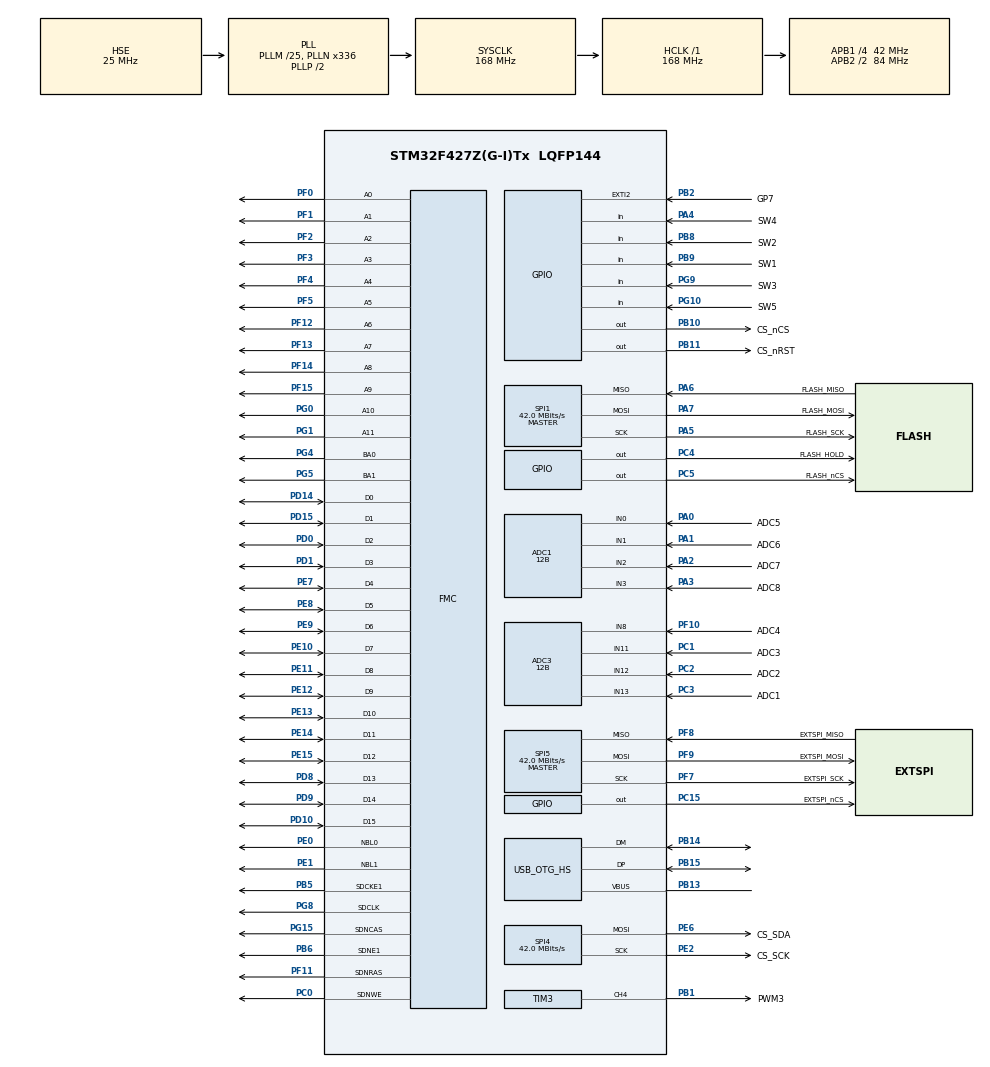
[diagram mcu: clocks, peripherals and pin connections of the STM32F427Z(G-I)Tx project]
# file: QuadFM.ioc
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ADC1.Channel-0\#ChannelRegularConversion=ADC_CHANNEL_0
ADC1.ClockPrescaler=ADC_CLOCK_SYNC_PCLK_DIV8
ADC1.ContinuousConvMode=DISABLE
ADC1.DMAContinuousRequests=DISABLE
ADC1.DataAlign=ADC_DATAALIGN_RIGHT
ADC1.DiscontinuousConvMode=DISABLE
ADC1.EOCSelection=ADC_EOC_SINGLE_CONV
ADC1.EnableAnalogWatchDog=false
ADC1.ExternalTrigConv=ADC_SOFTWARE_START
ADC1.ExternalTrigConvEdge=ADC_EXTERNALTRIGCONVEDGE_NONE
ADC1.InjNumberOfConversion=0
ADC1.NbrOfConversion=1
ADC1.NbrOfConversionFlag=1
ADC1.Rank-0\#ChannelRegularConversion=1
ADC1.Resolution=ADC_RESOLUTION_12B
ADC1.SamplingTime-0\#ChannelRegularConversion=ADC_SAMPLETIME_3CYCLES
ADC1.ScanConvMode=DISABLE
ADC1.master=1
ADC3.Channel-31\#ChannelRegularConversion=ADC_CHANNEL_12
ADC3.Channel-32\#ChannelRegularConversion=ADC_CHANNEL_8
ADC3.Channel-33\#ChannelRegularConversion=ADC_CHANNEL_11
ADC3.Channel-34\#ChannelRegularConversion=ADC_CHANNEL_13
ADC3.ClockPrescaler=ADC_CLOCK_SYNC_PCLK_DIV8
ADC3.ContinuousConvMode=ENABLE
ADC3.DMAContinuousRequests=ENABLE
ADC3.DataAlign=ADC_DATAALIGN_RIGHT
ADC3.DiscontinuousConvMode=DISABLE
ADC3.EOCSelection=ADC_EOC_SEQ_CONV
ADC3.EnableAnalogWatchDog=false
ADC3.ExternalTrigConv=ADC_SOFTWARE_START
ADC3.ExternalTrigConvEdge=ADC_EXTERNALTRIGCONVEDGE_NONE
ADC3.InjNumberOfConversion=0
ADC3.NbrOfConversion=4
ADC3.NbrOfConversionFlag=1
ADC3.Rank-31\#ChannelRegularConversion=1
ADC3.Rank-32\#ChannelRegularConversion=2
ADC3.Rank-33\#ChannelRegularConversion=3
ADC3.Rank-34\#ChannelRegularConversion=4
ADC3.Resolution=ADC_RESOLUTION_12B
ADC3.SamplingTime-31\#ChannelRegularConversion=ADC_SAMPLETIME_144CYCLES
ADC3.SamplingTime-32\#ChannelRegularConversion=ADC_SAMPLETIME_144CYCLES
ADC3.SamplingTime-33\#ChannelRegularConversion=ADC_SAMPLETIME_144CYCLES
ADC3.SamplingTime-34\#ChannelRegularConversion=ADC_SAMPLETIME_144CYCLES
ADC3.ScanConvMode=ENABLE
Dma.ADC1.1.Direction=DMA_PERIPH_TO_MEMORY
Dma.ADC1.1.FIFOMode=DMA_FIFOMODE_DISABLE
Dma.ADC1.1.Instance=DMA2_Stream4
Dma.ADC1.1.MemDataAlignment=DMA_MDATAALIGN_HALFWORD
Dma.ADC1.1.MemInc=DMA_MINC_ENABLE
Dma.ADC1.1.Mode=DMA_NORMAL
Dma.ADC1.1.PeriphDataAlignment=DMA_PDATAALIGN_HALFWORD
Dma.ADC1.1.PeriphInc=DMA_PINC_DISABLE
Dma.ADC1.1.Priority=DMA_PRIORITY_LOW
Dma.ADC3.0.Direction=DMA_PERIPH_TO_MEMORY
Dma.ADC3.0.FIFOMode=DMA_FIFOMODE_DISABLE
Dma.ADC3.0.Instance=DMA2_Stream0
Dma.ADC3.0.MemDataAlignment=DMA_MDATAALIGN_HALFWORD
Dma.ADC3.0.MemInc=DMA_MINC_ENABLE
Dma.ADC3.0.Mode=DMA_CIRCULAR
Dma.ADC3.0.PeriphDataAlignment=DMA_PDATAALIGN_HALFWORD
Dma.ADC3.0.PeriphInc=DMA_PINC_DISABLE
Dma.ADC3.0.Priority=DMA_PRIORITY_LOW
Dma.Request0=ADC3
Dma.Request1=ADC1
FMC.CASLatency1=FMC_SDRAM_CAS_LATENCY_3
FMC.ExitSelfRefreshDelay1=6
FMC.LoadToActiveDelay1=2
FMC.RCDDelay1=2
FMC.RPDelay1=2
FMC.RPDelay2=2
FMC.ReadBurst1=FMC_SDRAM_RBURST_ENABLE
FMC.ReadBurst2=FMC_SDRAM_RBURST_ENABLE
FMC.ReadPipeDelay1=FMC_SDRAM_RPIPE_DELAY_0
FMC.RowCycleDelay1=6
FMC.RowCycleDelay2=6
FMC.SDClockPeriod1=FMC_SDRAM_CLOCK_PERIOD_2
FMC.SDClockPeriod2=FMC_SDRAM_CLOCK_PERIOD_2
FMC.SelfRefreshTime1=4
FMC.WriteRecoveryTime1=2
Mcu.Family=STM32F4
Mcu.Name=STM32F427Z(G-I)Tx
Mcu.Package=LQFP144
NVIC.DMA2_Stream0_IRQn=true\:0\:0\:true\:false\:true
NVIC.DMA2_Stream4_IRQn=true\:5\:0\:true\:false\:true
NVIC.EXTI2_IRQn=true\:10\:0\:true\:false\:true
NVIC.OTG_HS_IRQn=true\:8\:0\:true\:false\:true
NVIC.PriorityGroup=NVIC_PRIORITYGROUP_4
PA0/WKUP.GPIO_Label=ADC5
PA0/WKUP.Signal=ADCx_IN0
PA1.GPIO_Label=ADC6
PA1.Signal=SharedAnalog_PA1
PA13.Mode=Trace_Asynchronous_SW
PA13.Signal=SYS_JTMS-SWDIO
PA14.Mode=Trace_Asynchronous_SW
PA14.Signal=SYS_JTCK-SWCLK
PA2.GPIO_Label=ADC7
PA2.Signal=ADCx_IN2
PA3.GPIO_Label=ADC8
PA3.Signal=ADCx_IN3
PA4.GPIO_Label=SW4
PA4.Signal=GPIO_Input
PA5.GPIO_Label=FLASH_SCK
PA5.Mode=Full_Duplex_Master
PA5.Signal=SPI1_SCK
PA6.GPIO_Label=FLASH_MISO
PA6.Mode=Full_Duplex_Master
PA6.Signal=SPI1_MISO
PA7.GPIO_Label=FLASH_MOSI
PA7.Mode=Full_Duplex_Master
PA7.Signal=SPI1_MOSI
PB1.GPIO_Label=PWM3
PB1.Signal=S_TIM3_CH4
PB10.GPIO_Label=CS_nCS
PB10.Signal=GPIO_Output
PB11.GPIO_Label=CS_nRST
PB11.Signal=GPIO_Output
PB13.Mode=Activate_VBUS_FS
PB13.Signal=USB_OTG_HS_VBUS
PB14.Mode=Device_Only_FS
PB14.Signal=USB_OTG_HS_DM
PB15.Mode=Device_Only_FS
PB15.Signal=USB_OTG_HS_DP
PB2/BOOT1.GPIO_Label=GP7
PB2/BOOT1.GPIO_ModeDefaultEXTI=GPIO_MODE_IT_RISING_FALLING
PB2/BOOT1.Signal=GPXTI2
PB3.Mode=Trace_Asynchronous_SW
PB3.Signal=SYS_JTDO-SWO
PB5.Mode=SdramChipSelect2_1
PB5.Signal=FMC_SDCKE1
PB6.Mode=SdramChipSelect2_1
PB6.Signal=FMC_SDNE1
PB8.GPIO_Label=SW2
PB8.Signal=GPIO_Input
PB9.GPIO_Label=SW1
PB9.Signal=GPIO_Input
PC0.Signal=FMC_SDNWE
PC1.GPIO_Label=ADC3
PC1.Signal=ADCx_IN11
PC15/OSC32_OUT.GPIO_Label=EXTSPI_nCS
PC15/OSC32_OUT.Signal=GPIO_Output
PC2.GPIO_Label=ADC2
PC2.Signal=ADCx_IN12
PC3.GPIO_Label=ADC1
PC3.Signal=ADCx_IN13
PC4.GPIO_Label=FLASH_HOLD
PC4.Signal=GPIO_Output
PC5.GPIO_Label=FLASH_nCS
PC5.Signal=GPIO_Output
PD0.Signal=FMC_D2_DA2
PD1.Signal=FMC_D3_DA3
PD10.Signal=FMC_D15_DA15
PD14.Signal=FMC_D0_DA0
PD15.Signal=FMC_D1_DA1
PD8.Signal=FMC_D13_DA13
PD9.Signal=FMC_D14_DA14
PE0.Signal=FMC_NBL0
PE1.Signal=FMC_NBL1
PE10.Signal=FMC_D7_DA7
PE11.Signal=FMC_D8_DA8
PE12.Signal=FMC_D9_DA9
PE13.Signal=FMC_D10_DA10
PE14.Signal=FMC_D11_DA11
PE15.Signal=FMC_D12_DA12
PE2.GPIO_Label=CS_SCK
PE2.Mode=TX_Only_Simplex_Unidirect_Master
PE2.Signal=SPI4_SCK
PE6.GPIO_Label=CS_SDA
PE6.Mode=TX_Only_Simplex_Unidirect_Master
PE6.Signal=SPI4_MOSI
PE7.Signal=FMC_D4_DA4
PE8.Signal=FMC_D5_DA5
PE9.Signal=FMC_D6_DA6
PF0.Signal=FMC_A0
PF1.Signal=FMC_A1
PF10.GPIO_Label=ADC4
PF10.Mode=IN8
PF10.Signal=ADC3_IN8
PF11.Signal=FMC_SDNRAS
PF12.Signal=FMC_A6
PF13.Signal=FMC_A7
PF14.Signal=FMC_A8
PF15.Signal=FMC_A9
PF2.Signal=FMC_A2
PF3.Signal=FMC_A3
PF4.Signal=FMC_A4
PF5.Signal=FMC_A5
PF7.GPIO_Label=EXTSPI_SCK
PF7.Mode=Full_Duplex_Master
PF7.Signal=SPI5_SCK
PF8.GPIO_Label=EXTSPI_MISO
PF8.Mode=Full_Duplex_Master
PF8.Signal=SPI5_MISO
PF9.GPIO_Label=EXTSPI_MOSI
PF9.Mode=Full_Duplex_Master
PF9.Signal=SPI5_MOSI
PG0.Signal=FMC_A10
PG1.Signal=FMC_A11
PG10.GPIO_Label=SW5
PG10.Signal=GPIO_Input
PG15.Signal=FMC_SDNCAS
PG4.Signal=FMC_A14_BA0
PG5.Signal=FMC_A15_BA1
PG8.Signal=FMC_SDCLK
PG9.GPIO_Label=SW3
PG9.Signal=GPIO_Input
PH0/OSC_IN.Mode=HSE-External-Oscillator
PH0/OSC_IN.Signal=RCC_OSC_IN
PH1/OSC_OUT.Mode=HSE-External-Oscillator
PH1/OSC_OUT.Signal=RCC_OSC_OUT
ProjectManager.HeapSize=0x200
ProjectManager.StackSize=0x400
ProjectManager.TargetToolchain=MDK-ARM V5
RCC.48MHZClocksFreq_Value=48000000
RCC.AHBFreq_Value=168000000
RCC.APB1CLKDivider=RCC_HCLK_DIV4
RCC.APB1Freq_Value=42000000
RCC.APB1TimFreq_Value=84000000
RCC.APB2CLKDivider=RCC_HCLK_DIV2
RCC.APB2Freq_Value=84000000
RCC.APB2TimFreq_Value=168000000
RCC.CortexFreq_Value=168000000
RCC.HCLKFreq_Value=168000000
RCC.HSE_VALUE=25000000
RCC.HSI_VALUE=16000000
RCC.LSE_VALUE=32768
RCC.PLLM=25
RCC.PLLN=336
RCC.PLLQ=7
RCC.PLLSAIN=100
RCC.SYSCLKFreq_VALUE=168000000
RCC.SYSCLKSource=RCC_SYSCLKSOURCE_PLLCLK
RCC.USBFreq_Value=48000000
RCC.VCOOutputFreq_Value=336000000
SH.ADCx_IN0.0=ADC1_IN0,IN0
SH.ADCx_IN11.0=ADC3_IN11,IN11
SH.ADCx_IN12.0=ADC3_IN12,IN12
SH.ADCx_IN13.0=ADC3_IN13,IN13
SH.ADCx_IN2.0=ADC1_IN2,IN2
SH.ADCx_IN3.0=ADC1_IN3,IN3
SH.FMC_A0.0=FMC_A0,12b-sda1
SH.FMC_A1.0=FMC_A1,12b-sda1
SH.FMC_A10.0=FMC_A10,12b-sda1
SH.FMC_A11.0=FMC_A11,12b-sda1
SH.FMC_A14_BA0.0=FMC_BA0,FourSdramBanks1
SH.FMC_A15_BA1.0=FMC_BA1,FourSdramBanks1
SH.FMC_A2.0=FMC_A2,12b-sda1
SH.FMC_A3.0=FMC_A3,12b-sda1
SH.FMC_A4.0=FMC_A4,12b-sda1
SH.FMC_A5.0=FMC_A5,12b-sda1
SH.FMC_A6.0=FMC_A6,12b-sda1
SH.FMC_A7.0=FMC_A7,12b-sda1
SH.FMC_A8.0=FMC_A8,12b-sda1
SH.FMC_A9.0=FMC_A9,12b-sda1
SH.FMC_D0_DA0.0=FMC_D0,sd-16b-d1
SH.FMC_D10_DA10.0=FMC_D10,sd-16b-d1
SH.FMC_D11_DA11.0=FMC_D11,sd-16b-d1
SH.FMC_D12_DA12.0=FMC_D12,sd-16b-d1
SH.FMC_D13_DA13.0=FMC_D13,sd-16b-d1
SH.FMC_D14_DA14.0=FMC_D14,sd-16b-d1
SH.FMC_D15_DA15.0=FMC_D15,sd-16b-d1
SH.FMC_D1_DA1.0=FMC_D1,sd-16b-d1
SH.FMC_D2_DA2.0=FMC_D2,sd-16b-d1
SH.FMC_D3_DA3.0=FMC_D3,sd-16b-d1
SH.FMC_D4_DA4.0=FMC_D4,sd-16b-d1
SH.FMC_D5_DA5.0=FMC_D5,sd-16b-d1
SH.FMC_D6_DA6.0=FMC_D6,sd-16b-d1
SH.FMC_D7_DA7.0=FMC_D7,sd-16b-d1
SH.FMC_D8_DA8.0=FMC_D8,sd-16b-d1
SH.FMC_D9_DA9.0=FMC_D9,sd-16b-d1
SH.FMC_NBL0.0=FMC_NBL0,Sd2ByteEnable1
SH.FMC_NBL1.0=FMC_NBL1,Sd2ByteEnable1
SH.FMC_SDCLK.0=FMC_SDCLK,12b-sda1
SH.FMC_SDNCAS.0=FMC_SDNCAS,12b-sda1
SH.FMC_SDNRAS.0=FMC_SDNRAS,12b-sda1
SH.FMC_SDNWE.0=FMC_SDNWE,12b-sda1
SH.S_TIM3_CH4.0=TIM3_CH4,PWM Generation4 CH4
SH.SharedAnalog_PA1.0=GPIO_Analog
SH.SharedAnalog_PA1.1=ADC1_IN1,IN1
SPI1.CalculateBaudRate=42.0 MBits/s
SPI1.Direction=SPI_DIRECTION_2LINES
SPI1.Mode=SPI_MODE_MASTER
SPI1.VirtualType=VM_MASTER
SPI4.CalculateBaudRate=42.0 MBits/s
SPI4.Direction=SPI_DIRECTION_2LINES
SPI4.Mode=SPI_MODE_MASTER
SPI4.VirtualType=VM_MASTER
SPI5.CalculateBaudRate=42.0 MBits/s
SPI5.Direction=SPI_DIRECTION_2LINES
SPI5.Mode=SPI_MODE_MASTER
SPI5.VirtualType=VM_MASTER
TIM3.Channel-PWM\ Generation4\ CH4=TIM_CHANNEL_4
TIM3.Period=1000
TIM3.Prescaler=100
TIM3.Pulse-PWM\ Generation4\ CH4=1000
USB_OTG_HS.VirtualMode-Device_Only_FS=Device_Only_FS
board=QuadFM

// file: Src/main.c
/**
  ******************************************************************************
  * File Name          : main.c
  * Description        : Main program body
  ******************************************************************************
  ** This notice applies to any and all portions of this file
  * that are not between comment pairs USER CODE BEGIN and
  * USER CODE END. Other portions of this file, whether
  * inserted by the user or by software development tools
  * are owned by their respective copyright owners.
  *
  * COPYRIGHT(c) 2017 STMicroelectronics
  *
  * Redistribution and use in source and binary forms, with or without modification,
  * are permitted provided that the following conditions are met:
  *   1. Redistributions of source code must retain the above copyright notice,
  *      this list of conditions and the following disclaimer.
  *   2. Redistributions in binary form must reproduce the above copyright notice,
  *      this list of conditions and the following disclaimer in the documentation
  *      and/or other materials provided with the distribution.
  *   3. Neither the name of STMicroelectronics nor the names of its contributors
  *      may be used to endorse or promote products derived from this software
  *      without specific prior written permission.
  *
  * THIS SOFTWARE IS PROVIDED BY THE COPYRIGHT HOLDERS AND CONTRIBUTORS "AS IS"
  * AND ANY EXPRESS OR IMPLIED WARRANTIES, INCLUDING, BUT NOT LIMITED TO, THE
  * IMPLIED WARRANTIES OF MERCHANTABILITY AND FITNESS FOR A PARTICULAR PURPOSE ARE
  * DISCLAIMED. IN NO EVENT SHALL THE COPYRIGHT HOLDER OR CONTRIBUTORS BE LIABLE
  * FOR ANY DIRECT, INDIRECT, INCIDENTAL, SPECIAL, EXEMPLARY, OR CONSEQUENTIAL
  * DAMAGES (INCLUDING, BUT NOT LIMITED TO, PROCUREMENT OF SUBSTITUTE GOODS OR
  * SERVICES; LOSS OF USE, DATA, OR PROFITS; OR BUSINESS INTERRUPTION) HOWEVER
  * CAUSED AND ON ANY THEORY OF LIABILITY, WHETHER IN CONTRACT, STRICT LIABILITY,
  * OR TORT (INCLUDING NEGLIGENCE OR OTHERWISE) ARISING IN ANY WAY OUT OF THE USE
  * OF THIS SOFTWARE, EVEN IF ADVISED OF THE POSSIBILITY OF SUCH DAMAGE.
  *
  ******************************************************************************
  */
#include "main.h"
#include "stm32f4xx_hal.h"

/* USER CODE BEGIN Includes */

#include "HAL_ToggleSwitches.h"
#include "TLC5971.h"
#include "Flash_S25FL.h"

/* USER CODE END Includes */

ADC_HandleTypeDef hadc1;
ADC_HandleTypeDef hadc3;
DMA_HandleTypeDef hdma_adc1;
DMA_HandleTypeDef hdma_adc3;

SPI_HandleTypeDef hspi1;
SPI_HandleTypeDef hspi4;
SPI_HandleTypeDef hspi5;

TIM_HandleTypeDef htim3;

PCD_HandleTypeDef hpcd_USB_OTG_HS;

SDRAM_HandleTypeDef hsdram1;

/* USER CODE BEGIN PV */
/* Private variables ---------------------------------------------------------*/

/* USER CODE END PV */

void SystemClock_Config(void);
static void MX_GPIO_Init(void);
static void MX_DMA_Init(void);
static void MX_ADC3_Init(void);
static void MX_FMC_Init(void);
static void MX_SPI5_Init(void);
static void MX_TIM3_Init(void);
static void MX_ADC1_Init(void);
static void MX_SPI1_Init(void);
static void MX_SPI4_Init(void);
static void MX_USB_OTG_HS_PCD_Init(void);

void HAL_TIM_MspPostInit(TIM_HandleTypeDef *htim);

/* USER CODE BEGIN PFP */
/* Private function prototypes -----------------------------------------------*/

/* USER CODE END PFP */

int main(void)
{

  /* MCU Configuration----------------------------------------------------------*/

  /* Reset of all peripherals, Initializes the Flash interface and the Systick. */
  HAL_Init();

  /* Configure the system clock */
  SystemClock_Config();

  /* Initialize all configured peripherals */
  MX_GPIO_Init();
  MX_DMA_Init();
  MX_ADC3_Init();
  MX_FMC_Init();
  MX_SPI5_Init();
  MX_TIM3_Init();
  MX_ADC1_Init();
  MX_SPI1_Init();
  MX_SPI4_Init();
  MX_USB_OTG_HS_PCD_Init();

  /* USER CODE BEGIN 2 */
	Flash_S25FL_init(&hspi1);
//	TLC5971_init(&hspi5);

//	TLC5971_SetOutput_GS(LED_A, LED_Red, 	0xFFFF);
//	TLC5971_SetOutput_GS(LED_A, LED_Green,0xFFFF);
//	TLC5971_SetOutput_GS(LED_A, LED_Blue, 0xFFFF);

//	TLC5971_SetOutput_GS(LED_B, LED_Red, 	0xFFFF);
//	TLC5971_SetOutput_GS(LED_B, LED_Green,0xFFFF);
//	TLC5971_SetOutput_GS(LED_B, LED_Blue, 0xFFFF);

//	TLC5971_SetOutput_GS(LED_C, LED_Red, 	0xFFFF);
//	TLC5971_SetOutput_GS(LED_C, LED_Green,0xFFFF);
//	TLC5971_SetOutput_GS(LED_C, LED_Blue, 0xFFFF);

//	TLC5971_SetOutput_GS(LED_D, LED_Red, 	0xFFFF);
//	TLC5971_SetOutput_GS(LED_D, LED_Green,0xFFFF);
//	TLC5971_SetOutput_GS(LED_D, LED_Blue, 0xFFFF);

//	TLC5971_SetOutput_BC(LED_Red, 	 0x08);
//	TLC5971_SetOutput_BC(LED_Green,  0x02);
//	TLC5971_SetOutput_BC(LED_Blue,   0x05);

//	TLC5971_Settings(REG_DSRPT);
//	TLC5971_Update();
  /* USER CODE END 2 */

  /* Infinite loop */
  /* USER CODE BEGIN WHILE */
  while (1)
  {
		HAL_Delay(100);
		Flash_S25FL_Test();

  /* USER CODE END WHILE */

  }

}

/** System Clock Configuration
*/
void SystemClock_Config(void)
{

  RCC_OscInitTypeDef RCC_OscInitStruct;
  RCC_ClkInitTypeDef RCC_ClkInitStruct;

    /**Configure the main internal regulator output voltage
    */
  __HAL_RCC_PWR_CLK_ENABLE();

  __HAL_PWR_VOLTAGESCALING_CONFIG(PWR_REGULATOR_VOLTAGE_SCALE1);

    /**Initializes the CPU, AHB and APB busses clocks
    */
  RCC_OscInitStruct.OscillatorType = RCC_OSCILLATORTYPE_HSE;
  RCC_OscInitStruct.HSEState = RCC_HSE_ON;
  RCC_OscInitStruct.PLL.PLLState = RCC_PLL_ON;
  RCC_OscInitStruct.PLL.PLLSource = RCC_PLLSOURCE_HSE;
  RCC_OscInitStruct.PLL.PLLM = 25;
  RCC_OscInitStruct.PLL.PLLN = 336;
  RCC_OscInitStruct.PLL.PLLP = RCC_PLLP_DIV2;
  RCC_OscInitStruct.PLL.PLLQ = 7;
  if (HAL_RCC_OscConfig(&RCC_OscInitStruct) != HAL_OK)
  {
    _Error_Handler(__FILE__, __LINE__);
  }

    /**Initializes the CPU, AHB and APB busses clocks
    */
  RCC_ClkInitStruct.ClockType = RCC_CLOCKTYPE_HCLK|RCC_CLOCKTYPE_SYSCLK
                              |RCC_CLOCKTYPE_PCLK1|RCC_CLOCKTYPE_PCLK2;
  RCC_ClkInitStruct.SYSCLKSource = RCC_SYSCLKSOURCE_PLLCLK;
  RCC_ClkInitStruct.AHBCLKDivider = RCC_SYSCLK_DIV1;
  RCC_ClkInitStruct.APB1CLKDivider = RCC_HCLK_DIV4;
  RCC_ClkInitStruct.APB2CLKDivider = RCC_HCLK_DIV2;

  if (HAL_RCC_ClockConfig(&RCC_ClkInitStruct, FLASH_LATENCY_5) != HAL_OK)
  {
    _Error_Handler(__FILE__, __LINE__);
  }

    /**Configure the Systick interrupt time
    */
  HAL_SYSTICK_Config(HAL_RCC_GetHCLKFreq()/1000);

    /**Configure the Systick
    */
  HAL_SYSTICK_CLKSourceConfig(SYSTICK_CLKSOURCE_HCLK);

  /* SysTick_IRQn interrupt configuration */
  HAL_NVIC_SetPriority(SysTick_IRQn, 0, 0);
}

/* ADC1 init function */
static void MX_ADC1_Init(void)
{

  ADC_ChannelConfTypeDef sConfig;

    /**Configure the global features of the ADC (Clock, Resolution, Data Alignment and number of conversion)
    */
  hadc1.Instance = ADC1;
  hadc1.Init.ClockPrescaler = ADC_CLOCK_SYNC_PCLK_DIV8;
  hadc1.Init.Resolution = ADC_RESOLUTION_12B;
  hadc1.Init.ScanConvMode = DISABLE;
  hadc1.Init.ContinuousConvMode = DISABLE;
  hadc1.Init.DiscontinuousConvMode = DISABLE;
  hadc1.Init.ExternalTrigConvEdge = ADC_EXTERNALTRIGCONVEDGE_NONE;
  hadc1.Init.ExternalTrigConv = ADC_SOFTWARE_START;
  hadc1.Init.DataAlign = ADC_DATAALIGN_RIGHT;
  hadc1.Init.NbrOfConversion = 1;
  hadc1.Init.DMAContinuousRequests = DISABLE;
  hadc1.Init.EOCSelection = ADC_EOC_SINGLE_CONV;
  if (HAL_ADC_Init(&hadc1) != HAL_OK)
  {
    _Error_Handler(__FILE__, __LINE__);
  }

    /**Configure for the selected ADC regular channel its corresponding rank in the sequencer and its sample time.
    */
  sConfig.Channel = ADC_CHANNEL_0;
  sConfig.Rank = 1;
  sConfig.SamplingTime = ADC_SAMPLETIME_3CYCLES;
  if (HAL_ADC_ConfigChannel(&hadc1, &sConfig) != HAL_OK)
  {
    _Error_Handler(__FILE__, __LINE__);
  }

}

/* ADC3 init function */
static void MX_ADC3_Init(void)
{

  ADC_ChannelConfTypeDef sConfig;

    /**Configure the global features of the ADC (Clock, Resolution, Data Alignment and number of conversion)
    */
  hadc3.Instance = ADC3;
  hadc3.Init.ClockPrescaler = ADC_CLOCK_SYNC_PCLK_DIV8;
  hadc3.Init.Resolution = ADC_RESOLUTION_12B;
  hadc3.Init.ScanConvMode = ENABLE;
  hadc3.Init.ContinuousConvMode = ENABLE;
  hadc3.Init.DiscontinuousConvMode = DISABLE;
  hadc3.Init.ExternalTrigConvEdge = ADC_EXTERNALTRIGCONVEDGE_NONE;
  hadc3.Init.ExternalTrigConv = ADC_SOFTWARE_START;
  hadc3.Init.DataAlign = ADC_DATAALIGN_RIGHT;
  hadc3.Init.NbrOfConversion = 4;
  hadc3.Init.DMAContinuousRequests = ENABLE;
  hadc3.Init.EOCSelection = ADC_EOC_SEQ_CONV;
  if (HAL_ADC_Init(&hadc3) != HAL_OK)
  {
    _Error_Handler(__FILE__, __LINE__);
  }

    /**Configure for the selected ADC regular channel its corresponding rank in the sequencer and its sample time.
    */
  sConfig.Channel = ADC_CHANNEL_12;
  sConfig.Rank = 1;
  sConfig.SamplingTime = ADC_SAMPLETIME_144CYCLES;
  if (HAL_ADC_ConfigChannel(&hadc3, &sConfig) != HAL_OK)
  {
    _Error_Handler(__FILE__, __LINE__);
  }

    /**Configure for the selected ADC regular channel its corresponding rank in the sequencer and its sample time.
    */
  sConfig.Channel = ADC_CHANNEL_8;
  sConfig.Rank = 2;
  if (HAL_ADC_ConfigChannel(&hadc3, &sConfig) != HAL_OK)
  {
    _Error_Handler(__FILE__, __LINE__);
  }

    /**Configure for the selected ADC regular channel its corresponding rank in the sequencer and its sample time.
    */
  sConfig.Channel = ADC_CHANNEL_11;
  sConfig.Rank = 3;
  if (HAL_ADC_ConfigChannel(&hadc3, &sConfig) != HAL_OK)
  {
    _Error_Handler(__FILE__, __LINE__);
  }

    /**Configure for the selected ADC regular channel its corresponding rank in the sequencer and its sample time.
    */
  sConfig.Channel = ADC_CHANNEL_13;
  sConfig.Rank = 4;
  if (HAL_ADC_ConfigChannel(&hadc3, &sConfig) != HAL_OK)
  {
    _Error_Handler(__FILE__, __LINE__);
  }

}

/* SPI1 init function */
static void MX_SPI1_Init(void)
{

  hspi1.Instance = SPI1;
  hspi1.Init.Mode = SPI_MODE_MASTER;
  hspi1.Init.Direction = SPI_DIRECTION_2LINES;
  hspi1.Init.DataSize = SPI_DATASIZE_8BIT;
  hspi1.Init.CLKPolarity = SPI_POLARITY_LOW;
  hspi1.Init.CLKPhase = SPI_PHASE_1EDGE;
  hspi1.Init.NSS = SPI_NSS_SOFT;
  hspi1.Init.BaudRatePrescaler = SPI_BAUDRATEPRESCALER_32;
  hspi1.Init.FirstBit = SPI_FIRSTBIT_MSB;
  hspi1.Init.TIMode = SPI_TIMODE_DISABLE;
  hspi1.Init.CRCCalculation = SPI_CRCCALCULATION_DISABLE;
  hspi1.Init.CRCPolynomial = 10;
  if (HAL_SPI_Init(&hspi1) != HAL_OK)
  {
    _Error_Handler(__FILE__, __LINE__);
  }

}

/* SPI4 init function */
static void MX_SPI4_Init(void)
{

  hspi4.Instance = SPI4;
  hspi4.Init.Mode = SPI_MODE_MASTER;
  hspi4.Init.Direction = SPI_DIRECTION_2LINES;
  hspi4.Init.DataSize = SPI_DATASIZE_8BIT;
  hspi4.Init.CLKPolarity = SPI_POLARITY_LOW;
  hspi4.Init.CLKPhase = SPI_PHASE_1EDGE;
  hspi4.Init.NSS = SPI_NSS_SOFT;
  hspi4.Init.BaudRatePrescaler = SPI_BAUDRATEPRESCALER_2;
  hspi4.Init.FirstBit = SPI_FIRSTBIT_MSB;
  hspi4.Init.TIMode = SPI_TIMODE_DISABLE;
  hspi4.Init.CRCCalculation = SPI_CRCCALCULATION_DISABLE;
  hspi4.Init.CRCPolynomial = 10;
  if (HAL_SPI_Init(&hspi4) != HAL_OK)
  {
    _Error_Handler(__FILE__, __LINE__);
  }
}

/* SPI5 init function */
static void MX_SPI5_Init(void)
{

  hspi5.Instance = SPI5;
  hspi5.Init.Mode = SPI_MODE_MASTER;
  hspi5.Init.Direction = SPI_DIRECTION_1LINE;
  hspi5.Init.DataSize = SPI_DATASIZE_8BIT;
  hspi5.Init.CLKPolarity = SPI_POLARITY_LOW;
  hspi5.Init.CLKPhase = SPI_PHASE_1EDGE;
  hspi5.Init.NSS = SPI_NSS_SOFT;
  hspi5.Init.BaudRatePrescaler = SPI_BAUDRATEPRESCALER_256;
  hspi5.Init.FirstBit = SPI_FIRSTBIT_MSB;
  hspi5.Init.TIMode = SPI_TIMODE_DISABLE;
  hspi5.Init.CRCCalculation = SPI_CRCCALCULATION_DISABLE;
  hspi5.Init.CRCPolynomial = 10;
  if (HAL_SPI_Init(&hspi5) != HAL_OK)
  {
    _Error_Handler(__FILE__, __LINE__);
  }
}

/* TIM3 init function */
static void MX_TIM3_Init(void)
{

  TIM_MasterConfigTypeDef sMasterConfig;
  TIM_OC_InitTypeDef sConfigOC;

  htim3.Instance = TIM3;
  htim3.Init.Prescaler = 100;
  htim3.Init.CounterMode = TIM_COUNTERMODE_UP;
  htim3.Init.Period = 1000;
  htim3.Init.ClockDivision = TIM_CLOCKDIVISION_DIV1;
  if (HAL_TIM_PWM_Init(&htim3) != HAL_OK)
  {
    _Error_Handler(__FILE__, __LINE__);
  }

  sMasterConfig.MasterOutputTrigger = TIM_TRGO_RESET;
  sMasterConfig.MasterSlaveMode = TIM_MASTERSLAVEMODE_DISABLE;
  if (HAL_TIMEx_MasterConfigSynchronization(&htim3, &sMasterConfig) != HAL_OK)
  {
    _Error_Handler(__FILE__, __LINE__);
  }

  sConfigOC.OCMode = TIM_OCMODE_PWM1;
  sConfigOC.Pulse = 1000;
  sConfigOC.OCPolarity = TIM_OCPOLARITY_HIGH;
  sConfigOC.OCFastMode = TIM_OCFAST_DISABLE;
  if (HAL_TIM_PWM_ConfigChannel(&htim3, &sConfigOC, TIM_CHANNEL_4) != HAL_OK)
  {
    _Error_Handler(__FILE__, __LINE__);
  }

  HAL_TIM_MspPostInit(&htim3);

}

/* USB_OTG_HS init function */
static void MX_USB_OTG_HS_PCD_Init(void)
{

  hpcd_USB_OTG_HS.Instance = USB_OTG_HS;
  hpcd_USB_OTG_HS.Init.dev_endpoints = 6;
  hpcd_USB_OTG_HS.Init.speed = PCD_SPEED_FULL;
  hpcd_USB_OTG_HS.Init.dma_enable = DISABLE;
  hpcd_USB_OTG_HS.Init.ep0_mps = DEP0CTL_MPS_64;
  hpcd_USB_OTG_HS.Init.phy_itface = USB_OTG_EMBEDDED_PHY;
  hpcd_USB_OTG_HS.Init.Sof_enable = DISABLE;
  hpcd_USB_OTG_HS.Init.low_power_enable = DISABLE;
  hpcd_USB_OTG_HS.Init.lpm_enable = DISABLE;
  hpcd_USB_OTG_HS.Init.vbus_sensing_enable = DISABLE;
  hpcd_USB_OTG_HS.Init.use_dedicated_ep1 = DISABLE;
  hpcd_USB_OTG_HS.Init.use_external_vbus = DISABLE;
  if (HAL_PCD_Init(&hpcd_USB_OTG_HS) != HAL_OK)
  {
    _Error_Handler(__FILE__, __LINE__);
  }

}

static void MX_DMA_Init(void)
{
  /* DMA controller clock enable */
  __HAL_RCC_DMA2_CLK_ENABLE();

  /* DMA interrupt init */
  /* DMA2_Stream0_IRQn interrupt configuration */
  HAL_NVIC_SetPriority(DMA2_Stream0_IRQn, 0, 0);
  HAL_NVIC_EnableIRQ(DMA2_Stream0_IRQn);
  /* DMA2_Stream4_IRQn interrupt configuration */
  HAL_NVIC_SetPriority(DMA2_Stream4_IRQn, 5, 0);
  HAL_NVIC_EnableIRQ(DMA2_Stream4_IRQn);

}
/* FMC initialization function */
static void MX_FMC_Init(void)
{
  FMC_SDRAM_TimingTypeDef SdramTiming;

  /** Perform the SDRAM1 memory initialization sequence
  */
  hsdram1.Instance = FMC_SDRAM_DEVICE;
  /* hsdram1.Init */
  hsdram1.Init.SDBank = FMC_SDRAM_BANK2;
  hsdram1.Init.ColumnBitsNumber = FMC_SDRAM_COLUMN_BITS_NUM_8;
  hsdram1.Init.RowBitsNumber = FMC_SDRAM_ROW_BITS_NUM_12;
  hsdram1.Init.MemoryDataWidth = FMC_SDRAM_MEM_BUS_WIDTH_16;
  hsdram1.Init.InternalBankNumber = FMC_SDRAM_INTERN_BANKS_NUM_4;
  hsdram1.Init.CASLatency = FMC_SDRAM_CAS_LATENCY_3;
  hsdram1.Init.WriteProtection = FMC_SDRAM_WRITE_PROTECTION_DISABLE;
  hsdram1.Init.SDClockPeriod = FMC_SDRAM_CLOCK_PERIOD_2;
  hsdram1.Init.ReadBurst = FMC_SDRAM_RBURST_ENABLE;
  hsdram1.Init.ReadPipeDelay = FMC_SDRAM_RPIPE_DELAY_0;
  /* SdramTiming */
  SdramTiming.LoadToActiveDelay = 2;
  SdramTiming.ExitSelfRefreshDelay = 6;
  SdramTiming.SelfRefreshTime = 4;
  SdramTiming.RowCycleDelay = 6;
  SdramTiming.WriteRecoveryTime = 2;
  SdramTiming.RPDelay = 2;
  SdramTiming.RCDDelay = 2;

  if (HAL_SDRAM_Init(&hsdram1, &SdramTiming) != HAL_OK)
  {
    _Error_Handler(__FILE__, __LINE__);
  }

}

/** Configure pins as
        * Analog
        * Input
        * Output
        * EVENT_OUT
        * EXTI
     PA1   ------> SharedAnalog_PA1
*/
static void MX_GPIO_Init(void)
{

  GPIO_InitTypeDef GPIO_InitStruct;

  /* GPIO Ports Clock Enable */
  __HAL_RCC_GPIOE_CLK_ENABLE();
  __HAL_RCC_GPIOC_CLK_ENABLE();
  __HAL_RCC_GPIOF_CLK_ENABLE();
  __HAL_RCC_GPIOH_CLK_ENABLE();
  __HAL_RCC_GPIOA_CLK_ENABLE();
  __HAL_RCC_GPIOB_CLK_ENABLE();
  __HAL_RCC_GPIOG_CLK_ENABLE();
  __HAL_RCC_GPIOD_CLK_ENABLE();

  /*Configure GPIO pin Output Level */
  HAL_GPIO_WritePin(GPIOC, EXTSPI_nCS_Pin|FLASH_HOLD_Pin|FLASH_nCS_Pin, GPIO_PIN_RESET);

  /*Configure GPIO pin Output Level */
  HAL_GPIO_WritePin(GPIOB, CS_nCS_Pin|CS_nRST_Pin, GPIO_PIN_RESET);

  /*Configure GPIO pins : EXTSPI_nCS_Pin FLASH_HOLD_Pin FLASH_nCS_Pin */
  GPIO_InitStruct.Pin = EXTSPI_nCS_Pin|FLASH_HOLD_Pin|FLASH_nCS_Pin;
  GPIO_InitStruct.Mode = GPIO_MODE_OUTPUT_PP;
  GPIO_InitStruct.Pull = GPIO_NOPULL;
  GPIO_InitStruct.Speed = GPIO_SPEED_FREQ_LOW;
  HAL_GPIO_Init(GPIOC, &GPIO_InitStruct);

  /*Configure GPIO pin : ADC6_Pin */
  GPIO_InitStruct.Pin = ADC6_Pin;
  GPIO_InitStruct.Mode = GPIO_MODE_ANALOG;
  GPIO_InitStruct.Pull = GPIO_NOPULL;
  HAL_GPIO_Init(ADC6_GPIO_Port, &GPIO_InitStruct);

  /*Configure GPIO pin : SW4_Pin */
  GPIO_InitStruct.Pin = SW4_Pin;
  GPIO_InitStruct.Mode = GPIO_MODE_INPUT;
  GPIO_InitStruct.Pull = GPIO_NOPULL;
  HAL_GPIO_Init(SW4_GPIO_Port, &GPIO_InitStruct);

  /*Configure GPIO pin : GP7_Pin */
  GPIO_InitStruct.Pin = GP7_Pin;
  GPIO_InitStruct.Mode = GPIO_MODE_IT_RISING_FALLING;
  GPIO_InitStruct.Pull = GPIO_NOPULL;
  HAL_GPIO_Init(GP7_GPIO_Port, &GPIO_InitStruct);

  /*Configure GPIO pins : CS_nCS_Pin CS_nRST_Pin */
  GPIO_InitStruct.Pin = CS_nCS_Pin|CS_nRST_Pin|FLASH_nWP_Pin;
  GPIO_InitStruct.Mode = GPIO_MODE_OUTPUT_PP;
  GPIO_InitStruct.Pull = GPIO_NOPULL;
  GPIO_InitStruct.Speed = GPIO_SPEED_FREQ_LOW;
  HAL_GPIO_Init(GPIOB, &GPIO_InitStruct);

  /*Configure GPIO pins : SW3_Pin SW5_Pin */
  GPIO_InitStruct.Pin = SW3_Pin|SW5_Pin;
  GPIO_InitStruct.Mode = GPIO_MODE_INPUT;
  GPIO_InitStruct.Pull = GPIO_NOPULL;
  HAL_GPIO_Init(GPIOG, &GPIO_InitStruct);

  /*Configure GPIO pins : SW2_Pin SW1_Pin */
  GPIO_InitStruct.Pin = SW2_Pin|SW1_Pin;
  GPIO_InitStruct.Mode = GPIO_MODE_INPUT;
  GPIO_InitStruct.Pull = GPIO_NOPULL;
  HAL_GPIO_Init(GPIOB, &GPIO_InitStruct);

  /* EXTI interrupt init*/
  HAL_NVIC_SetPriority(EXTI2_IRQn, 10, 0);
  HAL_NVIC_EnableIRQ(EXTI2_IRQn);

}

void _Error_Handler(char * file, int line)
{
  while(1)
  {
  }
}

/************************ (C) COPYRIGHT STMicroelectronics *****END OF FILE****/
